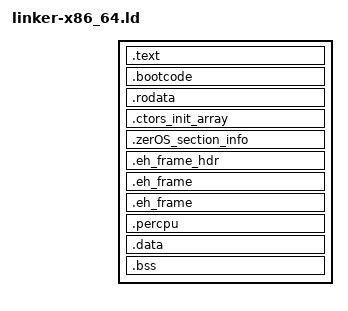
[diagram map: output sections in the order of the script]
/* TODO: Write a custom EFI-stub */

/* Tell the linker that we want an x86_64 ELF64 output file */
OUTPUT_FORMAT(elf64-x86-64)
OUTPUT_ARCH(i386:x86-64)

/* We want the symbol _start to be our entry point */
ENTRY(zerOS_entry_point)

/* Define the program headers we want so the bootloader gives us the right */
/* MMU permissions; this also allows us to exert more control over the linking */
/* process. */
PHDRS
{
    headers   PT_PHDR PHDRS;
    text      PT_LOAD FILEHDR PHDRS FLAGS(5);
    initcode  PT_LOAD FLAGS(5);
    percpu    PT_LOAD FLAGS(6);
    data      PT_LOAD FLAGS(6);
    rodata    PT_LOAD FLAGS(4);
    ehro      PT_LOAD FLAGS(4);
    ehrw      PT_LOAD FLAGS(6);
    /* dynamic   PT_DYNAMIC; */
}

SECTIONS
{
    /* We want to be placed in the topmost 2GiB of the address space, for optimisations */
    /* and because that is what the Limine spec mandates. */
    /* Any address in this region will do, but often 0xffffffff80000000 is chosen as */
    /* that is the beginning of the region. */
    /* Additionally, leave space for the ELF headers by adding SIZEOF_HEADERS to the */
    /* base load address. */
    . = 0xffffffff80000000 + SIZEOF_HEADERS;

    zerOS_kernel_start = ABSOLUTE(.) - SIZEOF_HEADERS;

    /* Emit zerOS_<section_name>_start and zerOS_<section_name>_end symbols for each section. */

    .text : ALIGN(CONSTANT(MAXPAGESIZE)) {
        *(.text .text.*)
    } :text

    .bootcode : ALIGN(CONSTANT(MAXPAGESIZE)) {
        *(.bootcode .bootcode.*)
    } :initcode

    .rodata : ALIGN(CONSTANT(MAXPAGESIZE)) {
        *(.rodata .rodata.*)
    } :rodata

    PROVIDE(__ctor_init_array_start = .);
    .ctors_init_array : ALIGN(CONSTANT(MAXPAGESIZE)) {
        KEEP(*(SORT_BY_INIT_PRIORITY(.ctors_init_array.*)))
    } :rodata
    PROVIDE(__ctor_init_array_end = .);

    .zerOS_section_info : ALIGN(CONSTANT(MAXPAGESIZE)) {
        
/* --- SECTIONINFO AUTOGENERATED BY /home/axel/Documents/programmation/osdev/zerOS/scripts/gensectioninfo.py, START --- */

/* --- SECTIONINFO START: text --- */
ASSERT(LOADADDR(.text) == ABSOLUTE(ADDR(.text)), "Section text is not loaded at the correct address");

. = ALIGN(CONSTANT(MAXPAGESIZE) / 64);
zerOS_text_start = LOADADDR(.text);

. = ALIGN(CONSTANT(MAXPAGESIZE) / 64);
zerOS_text_end = LOADADDR(.text) + SIZEOF(.text);
/* --- SECTIONINFO END: text --- */

/* --- SECTIONINFO START: bootcode --- */
ASSERT(LOADADDR(.bootcode) == ABSOLUTE(ADDR(.bootcode)), "Section bootcode is not loaded at the correct address");

. = ALIGN(CONSTANT(MAXPAGESIZE) / 64);
zerOS_bootcode_start = LOADADDR(.bootcode);

. = ALIGN(CONSTANT(MAXPAGESIZE) / 64);
zerOS_bootcode_end = LOADADDR(.bootcode) + SIZEOF(.bootcode);
/* --- SECTIONINFO END: bootcode --- */

/* --- SECTIONINFO START: ctors_init_array --- */
ASSERT(LOADADDR(.ctors_init_array) == ABSOLUTE(ADDR(.ctors_init_array)), "Section ctors_init_array is not loaded at the correct address");

. = ALIGN(CONSTANT(MAXPAGESIZE) / 64);
zerOS_ctors_init_array_start = LOADADDR(.ctors_init_array);

. = ALIGN(CONSTANT(MAXPAGESIZE) / 64);
zerOS_ctors_init_array_end = LOADADDR(.ctors_init_array) + SIZEOF(.ctors_init_array);
/* --- SECTIONINFO END: ctors_init_array --- */

/* --- SECTIONINFO START: rodata --- */
ASSERT(LOADADDR(.rodata) == ABSOLUTE(ADDR(.rodata)), "Section rodata is not loaded at the correct address");

. = ALIGN(CONSTANT(MAXPAGESIZE) / 64);
zerOS_rodata_start = LOADADDR(.rodata);

. = ALIGN(CONSTANT(MAXPAGESIZE) / 64);
zerOS_rodata_end = LOADADDR(.rodata) + SIZEOF(.rodata);
/* --- SECTIONINFO END: rodata --- */

/* --- SECTIONINFO START: data --- */
ASSERT(LOADADDR(.data) == ABSOLUTE(ADDR(.data)), "Section data is not loaded at the correct address");

. = ALIGN(CONSTANT(MAXPAGESIZE) / 64);
zerOS_data_start = LOADADDR(.data);

. = ALIGN(CONSTANT(MAXPAGESIZE) / 64);
zerOS_data_end = LOADADDR(.data) + SIZEOF(.data);
/* --- SECTIONINFO END: data --- */

/* --- SECTIONINFO START: bss --- */
ASSERT(LOADADDR(.bss) == ABSOLUTE(ADDR(.bss)), "Section bss is not loaded at the correct address");

. = ALIGN(CONSTANT(MAXPAGESIZE) / 64);
zerOS_bss_start = LOADADDR(.bss);

. = ALIGN(CONSTANT(MAXPAGESIZE) / 64);
zerOS_bss_end = LOADADDR(.bss) + SIZEOF(.bss);
/* --- SECTIONINFO END: bss --- */

/* --- SECTIONINFO AUTOGENERATED BY /home/axel/Documents/programmation/osdev/zerOS/scripts/gensectioninfo.py, END --- */

    } :rodata

    .eh_frame_hdr : ALIGN(CONSTANT(MAXPAGESIZE)) {
        *(.eh_frame_hdr) *(.eh_frame_entry .eh_frame_entry.*)
    } :ehro

    .eh_frame : ALIGN(CONSTANT(MAXPAGESIZE)) ONLY_IF_RO {
        KEEP (*(.eh_frame)) *(.eh_frame.*)
    } :ehro
    
    .eh_frame : ALIGN(CONSTANT(MAXPAGESIZE)) ONLY_IF_RW {
        KEEP (*(.eh_frame)) *(.eh_frame.*)
    } :ehrw

    PROVIDE(__eh_frame = LOADADDR(.eh_frame));

    /* PROVIDE(__eh_frame = .); */
    /* .eh_frame : { */
    /*     KEEP (*(*.eh_frame)) */
    /*     KEEP (*(*.eh_frame.*)) */
    /* } :eh */

    .percpu : ALIGN(CONSTANT(MAXPAGESIZE)) {
        *(.percpu .percpu.*)
    } :percpu

    .data : ALIGN(CONSTANT(MAXPAGESIZE)) {
        *(.data .data.*)

        /* Place the sections that contain the Limine requests as part of the .data */
        /* output section. */
        KEEP(*(.requests_start_marker))
        KEEP(*(.requests))
        KEEP(*(.requests_end_marker))
    } :data

    /* NOTE: .bss needs to be the last thing mapped to :data, otherwise lots of */
    /* unnecessary zeros will be written to the binary. */
    /* If you need, for example, .init_array and .fini_array, those should be placed */
    /* above this. */
    .bss : ALIGN(CONSTANT(MAXPAGESIZE)) {
        *(.bss .bss.*)
        *(COMMON)
    } :data

    zerOS_kernel_end = ABSOLUTE(.);


    /* Discard .note.* and .eh_frame* since they may cause issues on some hosts. */
    /* Also discard the program interpreter section since we do not need one. This is */
    /* more or less equivalent to the --no-dynamic-linker linker flag, except that it */
    /* works with ld.gold. */
    /DISCARD/ : {
        /* *(.eh_frame*) */
        *(.note .note.*)
        *(.interp)
        *(.comment*)
        *(.gcc_except_table*)
        *(.note*)
        /* *(.rel.eh_frame*) */
    }
}

/* NOCROSSREFS_TO(.text, .bootcode) */

ASSERT(zerOS_kernel_start == 0xffffffff80000000, "zerOS_kernel_start is not at the correct address")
